# liliumFP1_application register map
Vendor: Nordic Semiconductor; Series: liliumFP1; File version: 1
CPU: CM33 r0p4, little endian, MPU, FPU, 3 interrupt priority bits, 480 interrupts
Registers are 32-bit, read-write, reset 0x0 unless marked. A register's access mark holds for its fields unless they carry their own. Offsets are from the block's base; [hi:lo] are bit positions; lines under a group give offsets from that group; 'fields as' and 'values as' point back to an identical list.

## GLOBAL_UARTE120_NS — UART with EasyDMA 0
Base 0x4F8E5000; alternate view of GLOBAL_SPIS120_NS
Same registers: GLOBAL_UARTE130_NS 0x4F9A5000 (alternate view of GLOBAL_SPIM130_NS), GLOBAL_UARTE131_NS 0x4F9A6000 (alternate view of GLOBAL_SPIM131_NS), GLOBAL_UARTE132_NS 0x4F9B5000 (alternate view of GLOBAL_SPIM132_NS), GLOBAL_UARTE133_NS 0x4F9B6000 (alternate view of GLOBAL_SPIM133_NS), GLOBAL_UARTE134_NS 0x4F9C5000 (alternate view of GLOBAL_SPIM134_NS), GLOBAL_UARTE135_NS 0x4F9C6000 (alternate view of GLOBAL_SPIM135_NS), GLOBAL_UARTE136_NS 0x4F9D5000 (alternate view of GLOBAL_SPIM136_NS), GLOBAL_UARTE137_NS 0x4F9D6000 (alternate view of GLOBAL_SPIM137_NS), GLOBAL_UARTE120_S 0x5F8E5000 (alternate view of GLOBAL_SPIS120_S), GLOBAL_UARTE130_S 0x5F9A5000 (alternate view of GLOBAL_SPIM130_S), GLOBAL_UARTE131_S 0x5F9A6000 (alternate view of GLOBAL_SPIM131_S), GLOBAL_UARTE132_S 0x5F9B5000 (alternate view of GLOBAL_SPIM132_S), GLOBAL_UARTE133_S 0x5F9B6000 (alternate view of GLOBAL_SPIM133_S), GLOBAL_UARTE134_S 0x5F9C5000 (alternate view of GLOBAL_SPIM134_S), GLOBAL_UARTE135_S 0x5F9C6000 (alternate view of GLOBAL_SPIM135_S), GLOBAL_UARTE136_S 0x5F9D5000 (alternate view of GLOBAL_SPIM136_S), GLOBAL_UARTE137_S 0x5F9D6000 (alternate view of GLOBAL_SPIM137_S)
0x00 TASKS_STARTRX wo — Start UART receiver
  [0] TASKS_STARTRX
    1=Trigger task
0x04 TASKS_STOPRX wo — Stop UART receiver
  [0] TASKS_STOPRX
    1=Trigger task
0x08 TASKS_STARTTX wo — Start UART transmitter
  [0] TASKS_STARTTX
    1=Trigger task
0x0C TASKS_STOPTX wo — Stop UART transmitter
  [0] TASKS_STOPTX
    1=Trigger task
0x1C TASKS_SUSPEND wo — Suspend UART transaction
  [0] TASKS_SUSPEND
    1=Trigger task
0x20 TASKS_RESUME wo — Resume UART transaction
  [0] TASKS_RESUME
    1=Trigger task
0x2C TASKS_FLUSHRX wo — Flush RX FIFO into RX buffer
  [0] TASKS_FLUSHRX
    1=Trigger task
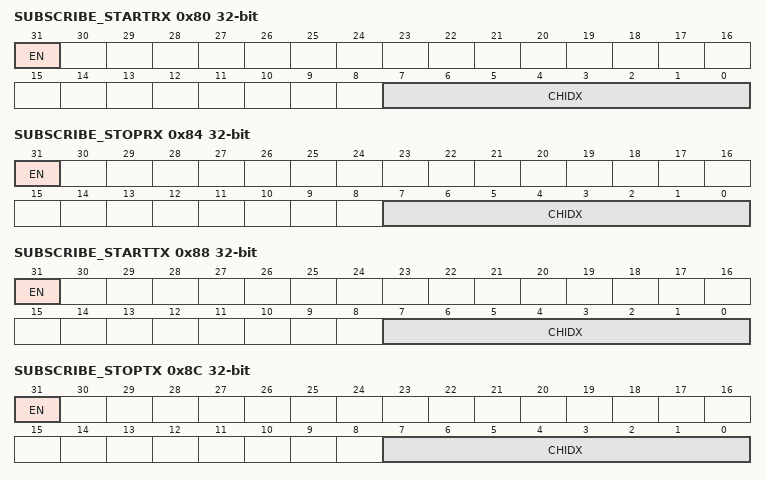
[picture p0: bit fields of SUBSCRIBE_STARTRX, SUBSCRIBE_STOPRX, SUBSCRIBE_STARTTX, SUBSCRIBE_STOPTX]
0x80 SUBSCRIBE_STARTRX — Subscribe configuration for task STARTRX
  [31] EN
    0=Disabled (Disable subscription); 1=Enabled (Enable subscription)
  [7:0] CHIDX — DPPI channel that task STARTRX will subscribe to
0x84 SUBSCRIBE_STOPRX — Subscribe configuration for task STOPRX
  [31] EN
    values as SUBSCRIBE_STARTRX.EN
  [7:0] CHIDX — DPPI channel that task STOPRX will subscribe to
0x88 SUBSCRIBE_STARTTX — Subscribe configuration for task STARTTX
  [31] EN
    values as SUBSCRIBE_STARTRX.EN
  [7:0] CHIDX — DPPI channel that task STARTTX will subscribe to
0x8C SUBSCRIBE_STOPTX — Subscribe configuration for task STOPTX
  [31] EN
    values as SUBSCRIBE_STARTRX.EN
  [7:0] CHIDX — DPPI channel that task STOPTX will subscribe to
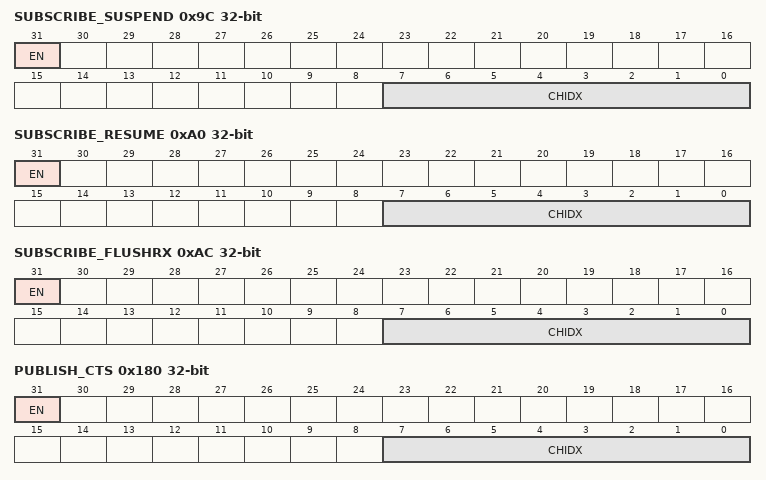
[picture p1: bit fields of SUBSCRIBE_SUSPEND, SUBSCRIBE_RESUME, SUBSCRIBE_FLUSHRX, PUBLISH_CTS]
0x9C SUBSCRIBE_SUSPEND — Subscribe configuration for task SUSPEND
  [31] EN
    values as SUBSCRIBE_STARTRX.EN
  [7:0] CHIDX — DPPI channel that task SUSPEND will subscribe to
0xA0 SUBSCRIBE_RESUME — Subscribe configuration for task RESUME
  [31] EN
    values as SUBSCRIBE_STARTRX.EN
  [7:0] CHIDX — DPPI channel that task RESUME will subscribe to
0xAC SUBSCRIBE_FLUSHRX — Subscribe configuration for task FLUSHRX
  [31] EN
    values as SUBSCRIBE_STARTRX.EN
  [7:0] CHIDX — DPPI channel that task FLUSHRX will subscribe to
0x100 EVENTS_CTS — CTS is activated (set low). Clear To Send.
  [0] EVENTS_CTS
    0=NotGenerated (Event not generated); 1=Generated (Event generated)
0x104 EVENTS_NCTS — CTS is deactivated (set high). Not Clear To Send.
  [0] EVENTS_NCTS
    values as EVENTS_CTS.EVENTS_CTS
0x108 EVENTS_RXDRDY — Data received in RXD (but potentially not yet transferred to Data RAM)
  [0] EVENTS_RXDRDY
    values as EVENTS_CTS.EVENTS_CTS
0x110 EVENTS_ENDRX — Receive buffer is filled up
  [0] EVENTS_ENDRX
    values as EVENTS_CTS.EVENTS_CTS
0x11C EVENTS_TXDRDY — Data sent from TXD
  [0] EVENTS_TXDRDY
    values as EVENTS_CTS.EVENTS_CTS
0x120 EVENTS_ENDTX — Last TX byte transmitted
  [0] EVENTS_ENDTX
    values as EVENTS_CTS.EVENTS_CTS
0x124 EVENTS_ERROR — Error detected
  [0] EVENTS_ERROR
    values as EVENTS_CTS.EVENTS_CTS
0x144 EVENTS_RXTO — Receiver timeout
  [0] EVENTS_RXTO
    values as EVENTS_CTS.EVENTS_CTS
0x14C EVENTS_RXSTARTED — UART receiver has started
  [0] EVENTS_RXSTARTED
    values as EVENTS_CTS.EVENTS_CTS
0x150 EVENTS_TXSTARTED — UART transmitter has started
  [0] EVENTS_TXSTARTED
    values as EVENTS_CTS.EVENTS_CTS
0x154 EVENTS_RTS — RX FIFO has only room for four more bytes before it overflows
  [0] EVENTS_RTS
    values as EVENTS_CTS.EVENTS_CTS
0x158 EVENTS_TXSTOPPED — Transmitter stopped
  [0] EVENTS_TXSTOPPED
    values as EVENTS_CTS.EVENTS_CTS
0x174 EVENTS_RXBUSERROR — This event is generated if an error occurs during the bus transfer. This event is generated on an AHB / AXI error response.
  [0] EVENTS_RXBUSERROR
    values as EVENTS_CTS.EVENTS_CTS
0x178 EVENTS_TXBUSERROR — This event is generated if an error occurs during the bus transfer. This event is generated on an AHB / AXI error response.
  [0] EVENTS_TXBUSERROR
    values as EVENTS_CTS.EVENTS_CTS
0x180 PUBLISH_CTS — Publish configuration for event CTS
  [31] EN
    0=Disabled (Disable publishing); 1=Enabled (Enable publishing)
  [7:0] CHIDX — DPPI channel that event CTS will publish to
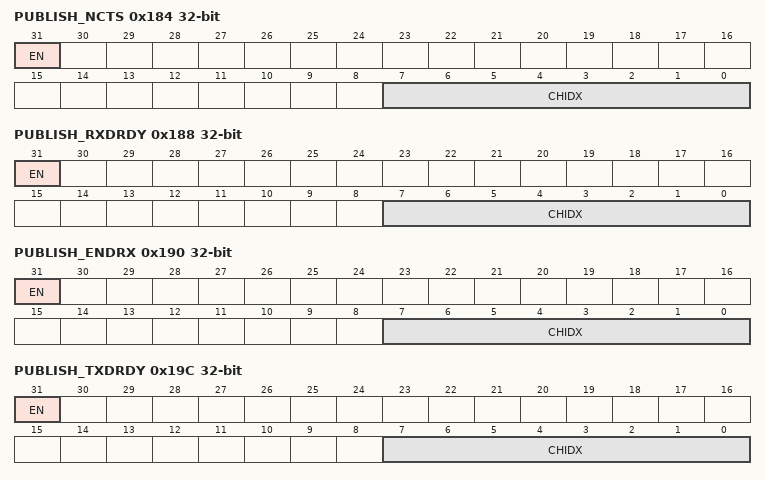
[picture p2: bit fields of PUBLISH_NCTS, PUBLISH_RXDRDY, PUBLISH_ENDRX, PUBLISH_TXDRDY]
0x184 PUBLISH_NCTS — Publish configuration for event NCTS
  [31] EN
    values as PUBLISH_CTS.EN
  [7:0] CHIDX — DPPI channel that event NCTS will publish to
0x188 PUBLISH_RXDRDY — Publish configuration for event RXDRDY
  [31] EN
    values as PUBLISH_CTS.EN
  [7:0] CHIDX — DPPI channel that event RXDRDY will publish to
0x190 PUBLISH_ENDRX — Publish configuration for event ENDRX
  [31] EN
    values as PUBLISH_CTS.EN
  [7:0] CHIDX — DPPI channel that event ENDRX will publish to
0x19C PUBLISH_TXDRDY — Publish configuration for event TXDRDY
  [31] EN
    values as PUBLISH_CTS.EN
  [7:0] CHIDX — DPPI channel that event TXDRDY will publish to
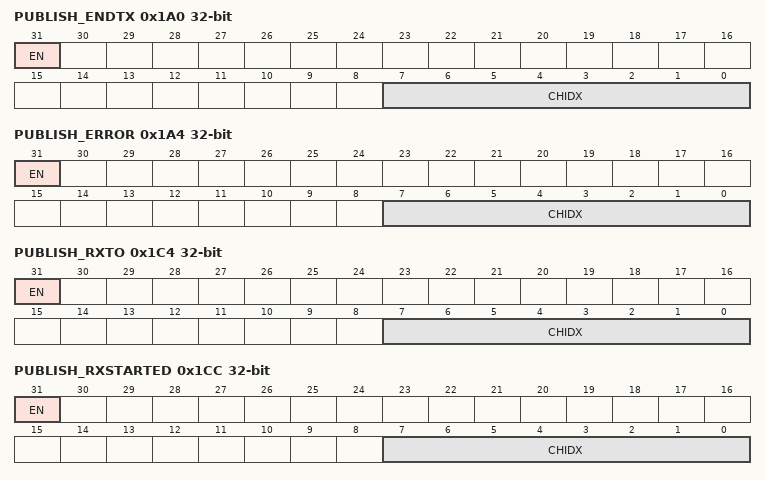
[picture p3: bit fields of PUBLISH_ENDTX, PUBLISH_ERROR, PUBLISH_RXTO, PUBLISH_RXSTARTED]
0x1A0 PUBLISH_ENDTX — Publish configuration for event ENDTX
  [31] EN
    values as PUBLISH_CTS.EN
  [7:0] CHIDX — DPPI channel that event ENDTX will publish to
0x1A4 PUBLISH_ERROR — Publish configuration for event ERROR
  [31] EN
    values as PUBLISH_CTS.EN
  [7:0] CHIDX — DPPI channel that event ERROR will publish to
0x1C4 PUBLISH_RXTO — Publish configuration for event RXTO
  [31] EN
    values as PUBLISH_CTS.EN
  [7:0] CHIDX — DPPI channel that event RXTO will publish to
0x1CC PUBLISH_RXSTARTED — Publish configuration for event RXSTARTED
  [31] EN
    values as PUBLISH_CTS.EN
  [7:0] CHIDX — DPPI channel that event RXSTARTED will publish to
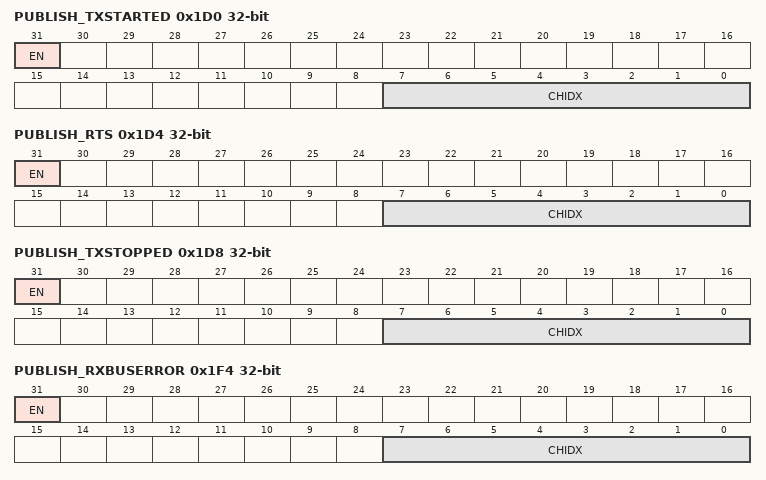
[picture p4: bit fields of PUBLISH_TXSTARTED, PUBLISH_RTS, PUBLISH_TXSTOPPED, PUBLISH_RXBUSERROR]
0x1D0 PUBLISH_TXSTARTED — Publish configuration for event TXSTARTED
  [31] EN
    values as PUBLISH_CTS.EN
  [7:0] CHIDX — DPPI channel that event TXSTARTED will publish to
0x1D4 PUBLISH_RTS — Publish configuration for event RTS
  [31] EN
    values as PUBLISH_CTS.EN
  [7:0] CHIDX — DPPI channel that event RTS will publish to
0x1D8 PUBLISH_TXSTOPPED — Publish configuration for event TXSTOPPED
  [31] EN
    values as PUBLISH_CTS.EN
  [7:0] CHIDX — DPPI channel that event TXSTOPPED will publish to
0x1F4 PUBLISH_RXBUSERROR — Publish configuration for event RXBUSERROR
  [31] EN
    values as PUBLISH_CTS.EN
  [7:0] CHIDX — DPPI channel that event RXBUSERROR will publish to
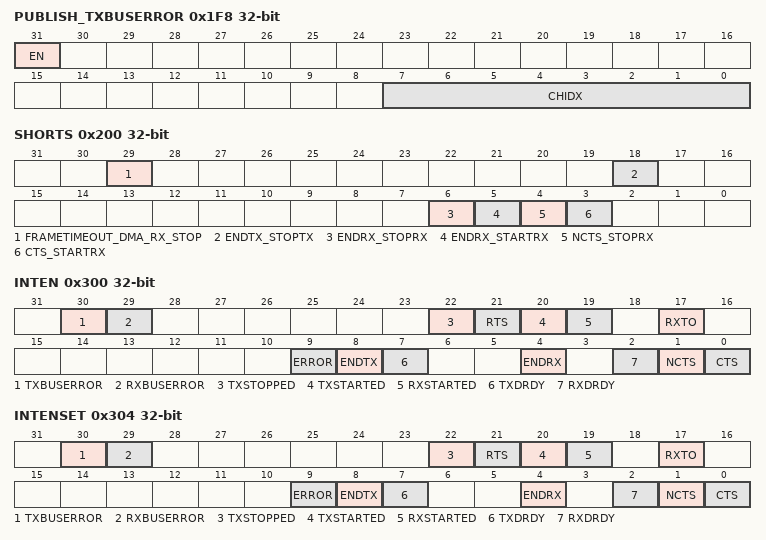
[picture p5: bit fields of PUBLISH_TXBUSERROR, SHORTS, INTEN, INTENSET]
0x1F8 PUBLISH_TXBUSERROR — Publish configuration for event TXBUSERROR
  [31] EN
    values as PUBLISH_CTS.EN
  [7:0] CHIDX — DPPI channel that event TXBUSERROR will publish to
0x200 SHORTS — Shortcuts between local events and tasks
  [all] fields
    0=Disabled (Disable shortcut); 1=Enabled (Enable shortcut)
  [29] FRAMETIMEOUT_DMA_RX_STOP — Shortcut between event FRAMETIMEOUT and task DMA.RX.STOP
  [18] ENDTX_STOPTX — Shortcut between event ENDTX and task STOPTX
  [6] ENDRX_STOPRX — Shortcut between event ENDRX and task STOPRX
  [5] ENDRX_STARTRX — Shortcut between event ENDRX and task STARTRX
  [4] NCTS_STOPRX — Shortcut between event NCTS and task STOPRX
  [3] CTS_STARTRX — Shortcut between event CTS and task STARTRX
0x300 INTEN — Enable or disable interrupt
  [all] fields
    0=Disabled; 1=Enabled
  [30] TXBUSERROR — Enable or disable interrupt for event TXBUSERROR
  [29] RXBUSERROR — Enable or disable interrupt for event RXBUSERROR
  [22] TXSTOPPED — Enable or disable interrupt for event TXSTOPPED
  [21] RTS — Enable or disable interrupt for event RTS
  [20] TXSTARTED — Enable or disable interrupt for event TXSTARTED
  [19] RXSTARTED — Enable or disable interrupt for event RXSTARTED
  [17] RXTO — Enable or disable interrupt for event RXTO
  [9] ERROR — Enable or disable interrupt for event ERROR
  [8] ENDTX — Enable or disable interrupt for event ENDTX
  [7] TXDRDY — Enable or disable interrupt for event TXDRDY
  [4] ENDRX — Enable or disable interrupt for event ENDRX
  [2] RXDRDY — Enable or disable interrupt for event RXDRDY
  [1] NCTS — Enable or disable interrupt for event NCTS
  [0] CTS — Enable or disable interrupt for event CTS
0x304 INTENSET — Enable interrupt
  [all] fields
    on read: 0=Disabled (Read: Disabled); 1=Enabled (Read: Enabled) | on write: 1=Set (Enable)
  [30] TXBUSERROR — Write '1' to enable interrupt for event TXBUSERROR
  [29] RXBUSERROR — Write '1' to enable interrupt for event RXBUSERROR
  [22] TXSTOPPED — Write '1' to enable interrupt for event TXSTOPPED
  [21] RTS — Write '1' to enable interrupt for event RTS
  [20] TXSTARTED — Write '1' to enable interrupt for event TXSTARTED
  [19] RXSTARTED — Write '1' to enable interrupt for event RXSTARTED
  [17] RXTO — Write '1' to enable interrupt for event RXTO
  [9] ERROR — Write '1' to enable interrupt for event ERROR
  [8] ENDTX — Write '1' to enable interrupt for event ENDTX
  [7] TXDRDY — Write '1' to enable interrupt for event TXDRDY
  [4] ENDRX — Write '1' to enable interrupt for event ENDRX
  [2] RXDRDY — Write '1' to enable interrupt for event RXDRDY
  [1] NCTS — Write '1' to enable interrupt for event NCTS
  [0] CTS — Write '1' to enable interrupt for event CTS
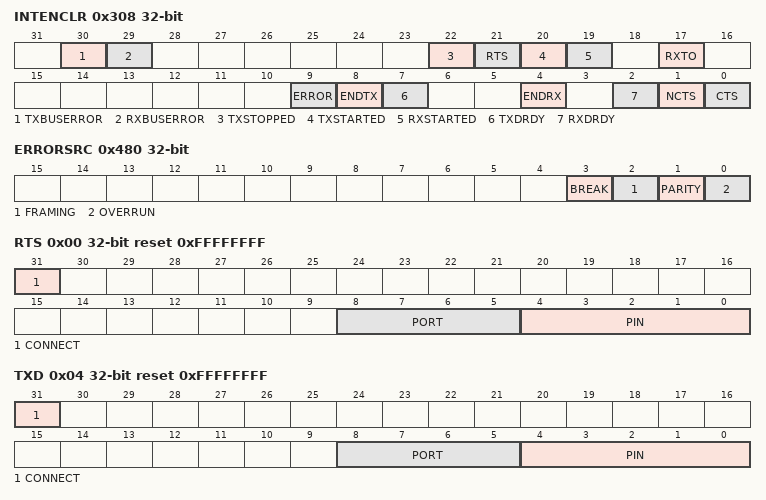
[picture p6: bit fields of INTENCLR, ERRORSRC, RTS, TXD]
0x308 INTENCLR — Disable interrupt
  [all] fields
    on read: 0=Disabled (Read: Disabled); 1=Enabled (Read: Enabled) | on write: 1=Clear (Disable)
  [30] TXBUSERROR — Write '1' to disable interrupt for event TXBUSERROR
  [29] RXBUSERROR — Write '1' to disable interrupt for event RXBUSERROR
  [22] TXSTOPPED — Write '1' to disable interrupt for event TXSTOPPED
  [21] RTS — Write '1' to disable interrupt for event RTS
  [20] TXSTARTED — Write '1' to disable interrupt for event TXSTARTED
  [19] RXSTARTED — Write '1' to disable interrupt for event RXSTARTED
  [17] RXTO — Write '1' to disable interrupt for event RXTO
  [9] ERROR — Write '1' to disable interrupt for event ERROR
  [8] ENDTX — Write '1' to disable interrupt for event ENDTX
  [7] TXDRDY — Write '1' to disable interrupt for event TXDRDY
  [4] ENDRX — Write '1' to disable interrupt for event ENDRX
  [2] RXDRDY — Write '1' to disable interrupt for event RXDRDY
  [1] NCTS — Write '1' to disable interrupt for event NCTS
  [0] CTS — Write '1' to disable interrupt for event CTS
0x480 ERRORSRC write-1-clears — Error source
  [all] fields
    on read: 0=NotPresent (Read: error not present); 1=Present (Read: error present)
  [3] BREAK — Break condition
  [2] FRAMING — Framing error occurred
  [1] PARITY — Parity error
  [0] OVERRUN — Overrun error
0x500 ENABLE — Enable UART
  [3:0] ENABLE — Enable or disable UARTE
    0=Disabled (Disable UARTE); 8=Enabled (Enable UARTE)
0x508 PSEL group — Unspecified
  0x00 RTS reset 0xFFFFFFFF — Pin select for RTS signal
    [31] CONNECT — Connection
      1=Disconnected; 0=Connected
    [8:5] PORT — Port number
    [4:0] PIN — Pin number
  0x04 TXD reset 0xFFFFFFFF — Pin select for TXD signal
    fields as PSEL.RTS
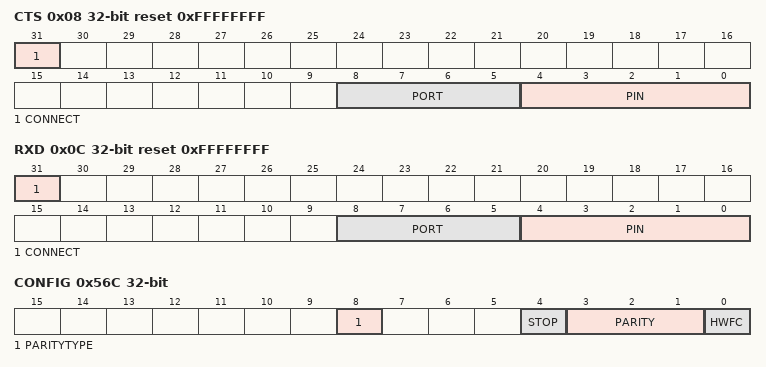
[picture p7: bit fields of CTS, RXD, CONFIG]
  0x08 CTS reset 0xFFFFFFFF — Pin select for CTS signal
    fields as PSEL.RTS
  0x0C RXD reset 0xFFFFFFFF — Pin select for RXD signal
    fields as PSEL.RTS
0x524 BAUDRATE reset 0x4000000 — Baud rate. Accuracy depends on the HFCLK source selected.
  [31:0] BAUDRATE
    0x4F000=Baud1200 (1200 baud (actual rate: 1205)); 0x9D000=Baud2400 (2400 baud (actual rate: 2396)); 0x13B000=Baud4800 (4800 baud (actual rate: 4808)); 0x275000=Baud9600 (9600 baud (actual rate: 9598)); 0x3AF000=Baud14400 (14400 baud (actual rate: 14401)); 0x4EA000=Baud19200 (19200 baud (actual rate: 19208)); 0x75C000=Baud28800 (28800 baud (actual rate: 28777)); 0x800000=Baud31250 (31250 baud); 0x9D0000=Baud38400 (38400 baud (actual rate: 38369)); 0xE50000=Baud56000 (56000 baud (actual rate: 55944)); 0xEB0000=Baud57600 (57600 baud (actual rate: 57554)); 0x13A9000=Baud76800 (76800 baud (actual rate: 76923)); 0x1D60000=Baud115200 (115200 baud (actual rate: 115108)); 0x3B00000=Baud230400 (230400 baud (actual rate: 231884)); 0x4000000=Baud250000 (250000 baud); 0x7400000=Baud460800 (460800 baud (actual rate: 457143)); 0xF000000=Baud921600 (921600 baud (actual rate: 941176)); 0x10000000=Baud1M (1 megabaud)
0x534 RXD group — RXD EasyDMA channel
  0x00 PTR — Data pointer
  0x04 MAXCNT — Maximum number of bytes in receive buffer
    [7:0] MAXCNT
  0x08 AMOUNT ro — Number of bytes transferred in the last transaction
    [7:0] AMOUNT
0x544 TXD group — TXD EasyDMA channel
  0x00 PTR — Data pointer
  0x04 MAXCNT — Maximum number of bytes in transmit buffer
    [7:0] MAXCNT
  0x08 AMOUNT ro — Number of bytes transferred in the last transaction
    [7:0] AMOUNT
0x56C CONFIG — Configuration of parity, hardware flow control, framesize, and packet timeout.
  [8] PARITYTYPE — Even or odd parity type
    0=Even parity; 1=Odd (Odd parity)
  [4] STOP — Stop bits
    0=One (One stop bit); 1=Two (Two stop bits)
  [3:1] PARITY
    0=Excluded (Exclude parity bit); 7=Included (Include even parity bit)
  [0] HWFC — Hardware flow control
    0=Disabled; 1=Enabled
0x5B0 DMA group — Unspecified
  0x00 RX group — Unspecified
    0x00 TERMINATEONBUSERROR — Terminate the transaction if a BUSERROR event is detected.
      [0] ENABLE
        0=Disabled; 1=Enabled
    0x04 BUSERRORADDRESS — Address of transaction that generated the last BUSERROR event.
      [31:0] ADDRESS
  0x08 TX group — Unspecified
    0x00 TERMINATEONBUSERROR — Terminate the transaction if a BUSERROR event is detected.
      [0] ENABLE
        0=Disabled; 1=Enabled
    0x04 BUSERRORADDRESS — Address of transaction that generated the last BUSERROR event.
      [31:0] ADDRESS
